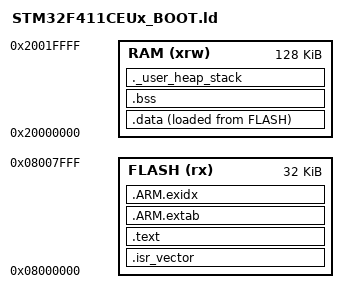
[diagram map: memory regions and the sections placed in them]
/* Linker script for STM32F411CEUx Bootloader (0x08000000-0x08007FFF) */

ENTRY(Reset_Handler)

_estack = ORIGIN(RAM) + LENGTH(RAM);

MEMORY
{
  FLASH (rx)  : ORIGIN = 0x08000000, LENGTH = 0x8000
  RAM   (xrw) : ORIGIN = 0x20000000, LENGTH = 0x20000
}

SECTIONS
{
  .isr_vector :
  {
    . = ALIGN(4);
    KEEP(*(.isr_vector))
    . = ALIGN(4);
  } > FLASH

  .text :
  {
    . = ALIGN(4);
    *(.text)
    *(.text*)
    *(.rodata)
    *(.rodata*)
    *(.glue_7)
    *(.glue_7t)
    *(.eh_frame)
    KEEP(*(.init))
    KEEP(*(.fini))
    . = ALIGN(4);
    _etext = .;
  } > FLASH

  .ARM.extab :
  {
    *(.ARM.extab* .gnu.linkonce.armextab.*)
  } > FLASH

  .ARM.exidx :
  {
    *(.ARM.exidx* .gnu.linkonce.armexidx.*)
  } > FLASH

  _sidata = LOADADDR(.data);

  .data :
  {
    . = ALIGN(4);
    _sdata = .;
    *(.data)
    *(.data*)
    . = ALIGN(4);
    _edata = .;
  } > RAM AT > FLASH

  .bss :
  {
    . = ALIGN(4);
    _sbss = .;
    *(.bss)
    *(.bss*)
    *(COMMON)
    . = ALIGN(4);
    _ebss = .;
  } > RAM

  ._user_heap_stack :
  {
    . = ALIGN(8);
    PROVIDE(end = .);
    PROVIDE(_end = .);
    . = . + 0x200; /* heap */
    . = . + 0x400; /* stack */
    . = ALIGN(8);
  } > RAM
}
